# STM32F373xC register map
File version: 1.0
Registers are 32-bit, read-write, reset 0x0 unless marked. A register's access mark holds for its fields unless they carry their own. Offsets are from the block's base; [hi:lo] are bit positions; lines under a group give offsets from that group; {n}, {i} and the like mark numbered series.

## ADC1 — Analog to Digital Converter
Base 0x40012400
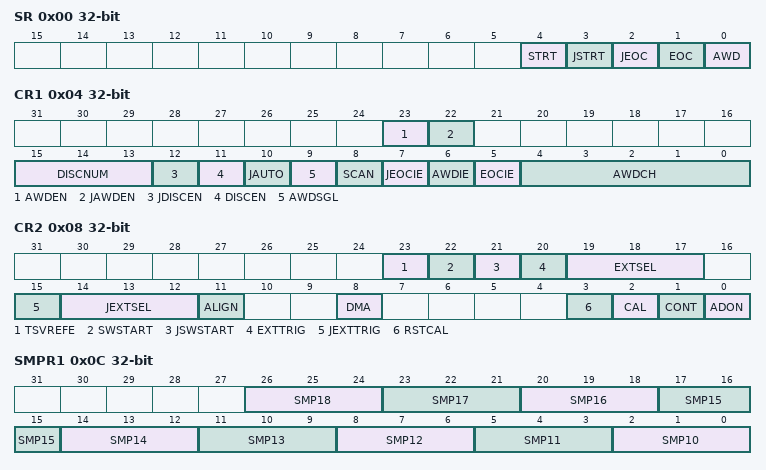
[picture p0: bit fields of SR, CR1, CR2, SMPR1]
0x00 SR — ADC status register
  [4] STRT — Regular channel Start flag
  [3] JSTRT — Injected channel Start flag
  [2] JEOC — Injected channel end of conversion
  [1] EOC — End of conversion
  [0] AWD — Analog watchdog flag
0x04 CR1 — ADC control register 1
  [23] AWDEN — Analog watchdog enable on regular channels
  [22] JAWDEN — Analog watchdog enable on injected channels
  [15:13] DISCNUM — DISCNUM[2:0] bits (Discontinuous mode channel count)
  [12] JDISCEN — Discontinuous mode on injected channels
    0=DISABLE (ADC group injected sequencer discontinuous mode disable); 1=DISCONT_1RANK (ADC group injected sequencer discontinuous mode enable with sequence interruption every rank)
  [11] DISCEN — Discontinuous mode on regular channels
  [10] JAUTO — Automatic injected group conversion
    0=INDEPENDENT (ADC group injected conversion trigger independent. Setting mandatory if ADC group injected injected trigger source is set to an external trigger.); 1=FROM_GRP_REGULAR (ADC group injected conversion trigger from ADC group regular. Setting compliant only with group injected trigger source set to SW start, without any further action on ADC group injected conversion start or stop: in this case, ADC group injected is controlled only from ADC group regular.)
  [9] AWDSGL — Enable the watchdog on a single channel in scan mode
  [8] SCAN — Scan mode
    0=DISABLE (ADC conversion is performed in unitary conversion mode (one channel converted, that defined in rank 1). Configuration of both groups regular and injected sequencers (sequence length, ...) is discarded: equivalent to length of 1 rank.); 1=ENABLE (ADC conversions are performed in sequence conversions mode, according to configuration of both groups regular and injected sequencers (sequence length, ...).)
  [7] JEOCIE — Interrupt enable for injected channels
  [6] AWDIE — Analog Watchdog interrupt enable
  [5] EOCIE — Interrupt enable for EOC
  [4:0] AWDCH — AWDCH[4:0] bits (Analog watchdog channel select bits)
0x08 CR2 — ADC control register 2
  [23] TSVREFE — Temperature Sensor and VREFINT Enable
    0=NONE (ADC measurement paths all disabled); 1=VREFINT (ADC measurement path to internal channel VrefInt)
  [22] SWSTART — Start Conversion of regular channels
  [21] JSWSTART — Start Conversion of injected channels
  [20] EXTTRIG — External Trigger Conversion mode for regular channels
  [19:17] EXTSEL — EXTSEL[2:0] bits (External Event Select for regular group)
    7=SOFTWARE (ADC group regular conversion trigger internal: SW start.); 3=EXT_TIM2_CH2 (ADC group regular conversion trigger from external IP: TIM2 channel 2 event (capture compare: input capture or output capture). Trigger edge set to rising edge (default setting).); 4=EXT_TIM3_TRGO (ADC group regular conversion trigger from external IP: TIM3 TRGO. Trigger edge set to rising edge (default setting).); 5=EXT_TIM4_CH2 (ADC group regular conversion trigger external from TIM4 CC4. Trigger edge set to rising edge (default setting).); 0=EXT_TIM19_TRGO (ADC group regular conversion trigger external from TIM19 TRGO. Trigger edge set to rising edge (default setting).); 1=EXT_TIM19_CH3 (ADC group regular conversion trigger external from TIM19 CC3. Trigger edge set to rising edge (default setting).); 2=EXT_TIM19_CH4 (ADC group regular conversion trigger external from TIM19 CC4. Trigger edge set to rising edge (default setting).); 6=EXT_EXTI_LINE11 (ADC group regular conversion trigger from external IP: external interrupt line 11. Trigger edge set to rising edge (default setting).)
  [15] JEXTTRIG — External Trigger Conversion mode for injected channels
  [14:12] JEXTSEL — JEXTSEL[2:0] bits (External event select for injected group)
    7=SOFTWARE (ADC group injected conversion trigger internal: SW start.. Trigger edge set to rising edge (default setting).); 2=EXT_TIM2_TRGO (ADC group injected conversion trigger from external IP: TIM2 TRG0. Trigger edge set to rising edge (default setting).); 3=EXT_TIM2_CH1 (ADC group injected conversion trigger from external IP: TIM2 channel 1 event (capture compare: input capture or output capture). Trigger edge set to rising edge (default setting).); 4=EXT_TIM3_CH4 (ADC group injected conversion trigger from external IP: TIM3 channel 4 event (capture compare: input capture or output capture). Trigger edge set to rising edge (default setting).); 5=EXT_TIM4_TRGO (ADC group injected conversion trigger from external IP: TIM4 TRG0. Trigger edge set to rising edge (default setting).); 0=EXT_TIM19_CH1 (ADC group injected conversion trigger external from TIM19 CC1. Trigger edge set to rising edge (default setting).); 1=EXT_TIM19_CH2 (ADC group injected conversion trigger external from TIM19 CC2. Trigger edge set to rising edge (default setting).); 6=EXT_EXTI_LINE15 (ADC group injected conversion trigger from external IP: external interrupt line 15. Trigger edge set to rising edge (default setting).)
  [11] ALIGN — Data Alignment
    0=RIGHT (ADC conversion data alignment: right aligned (alignment on data register LSB bit 0)); 1=LEFT (ADC conversion data alignment: left aligned (alignment on data register MSB bit 15))
  [8] DMA — Direct Memory access mode
    0=NONE (ADC conversions are not transferred by DMA); 1=UNLIMITED (ADC conversion data are transferred by DMA, in unlimited mode: DMA transfer requests are unlimited, whatever number of DMA data transferred (number of ADC conversions). This ADC mode is intended to be used with DMA mode circular.)
  [3] RSTCAL — Reset Calibration
  [2] CAL — A/D Calibration
  [1] CONT — Continuous Conversion
    0=SINGLE (ADC conversions are performed in single mode: one conversion per trigger); 1=CONTINUOUS (ADC conversions are performed in continuous mode: after the first trigger, following conversions launched successively automatically)
  [0] ADON — A/D Converter ON / OFF
0x0C SMPR1 — ADC sample time register 1
  [3n-28:3n-30] SMP{n} (n=10..18) — SMP{n}[2:0] bits (Channel {n} Sample time selection)
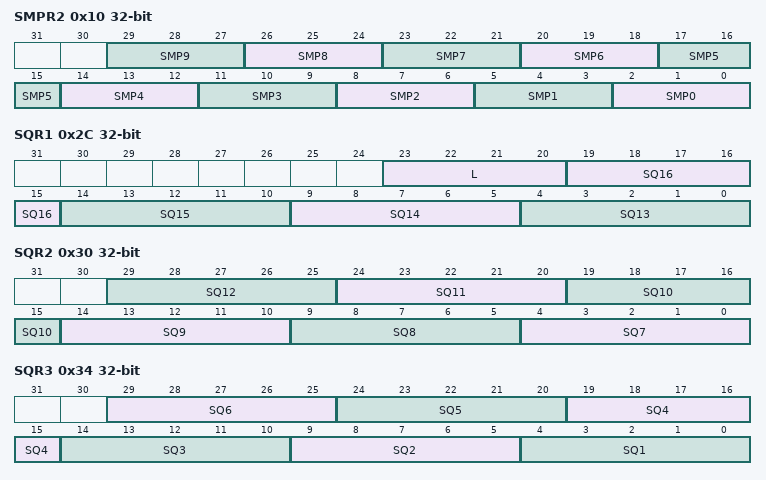
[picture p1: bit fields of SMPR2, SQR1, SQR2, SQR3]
0x10 SMPR2 — ADC sample time register 2
  [3n+2:3n] SMP{n} (n=0..9) — SMP{n}[2:0] bits (Channel {n} Sample time selection)
{0x10+4i} JOFR{i} (i=1..4) — ADC injected channel data
  [11:0] JOFFSET{i} — Data offset for injected channel {i}
0x24 HTR — ADC watchdog higher threshold register
  [11:0] HT — Analog watchdog high threshold
0x28 LTR — ADC watchdog lower threshold register
  [11:0] LT — Analog watchdog low threshold
0x2C SQR1 — ADC regular sequence register 1
  [23:20] L — L[3:0] bits (Regular channel sequence length)
    0=DISABLE (ADC group regular sequencer disable (equivalent to sequencer of 1 rank: ADC conversion on only 1 channel)); {v}=ENABLE_{v+1}RANKS (ADC group regular sequencer enable with {v+1} ranks in the sequence) (v=1..15)
  [5n-61:5n-65] SQ{n} (n=13..16) — SQ{n}[4:0] bits ({n}th conversion in regular sequence)
0x30 SQR2 — ADC regular sequence register 2
  [5n-31:5n-35] SQ{n} (n=7..12) — SQ{n}[4:0] bits ({n}th conversion in regular sequence)
0x34 SQR3 — ADC regular sequence register 3
  [29:25] SQ6 — SQ6[4:0] bits (6th conversion in regular sequence)
  [24:20] SQ5 — SQ5[4:0] bits (5th conversion in regular sequence)
  [19:15] SQ4 — SQ4[4:0] bits (4th conversion in regular sequence)
  [14:10] SQ3 — SQ3[4:0] bits (3rd conversion in regular sequence)
  [9:5] SQ2 — SQ2[4:0] bits (2nd conversion in regular sequence)
  [4:0] SQ1 — SQ1[4:0] bits (1st conversion in regular sequence)
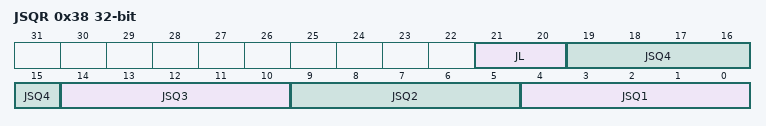
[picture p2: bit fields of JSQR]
0x38 JSQR — ADC injected sequence register
  [21:20] JL — JL[1:0] bits (Injected Sequence length)
    0=DISABLE (ADC group injected sequencer disable (equivalent to sequencer of 1 rank: ADC conversion on only 1 channel)); 1=ENABLE_2RANKS (ADC group injected sequencer enable with 2 ranks in the sequence); 2=ENABLE_3RANKS (ADC group injected sequencer enable with 3 ranks in the sequence); 3=ENABLE_4RANKS (ADC group injected sequencer enable with 4 ranks in the sequence)
  [19:15] JSQ4 — JSQ4[4:0] bits (4th conversion in injected sequence)
  [14:10] JSQ3 — JSQ3[4:0] bits (3rd conversion in injected sequence)
  [9:5] JSQ2 — JSQ2[4:0] bits (2nd conversion in injected sequence)
  [4:0] JSQ1 — JSQ1[4:0] bits (1st conversion in injected sequence)
{0x38+4i} JDR{i} (i=1..4) — ADC injected data register {i}
0x4C DR — ADC regular data register
  [15:0] DATA — Regular data
